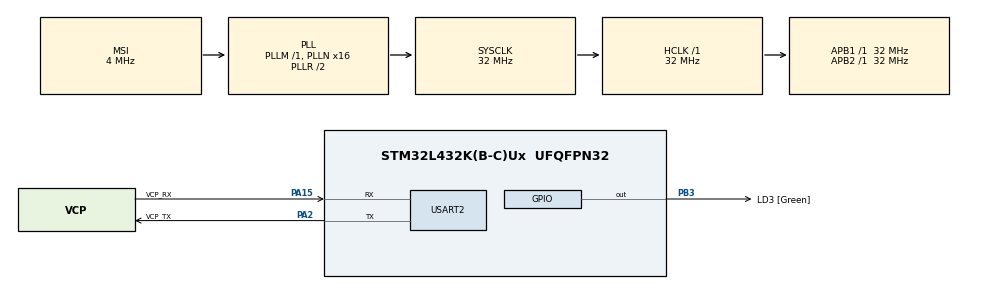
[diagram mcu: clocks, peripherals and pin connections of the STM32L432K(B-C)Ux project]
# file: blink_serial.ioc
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Mcu.Family=STM32L4
Mcu.Name=STM32L432K(B-C)Ux
Mcu.Package=UFQFPN32
NVIC.PriorityGroup=NVIC_PRIORITYGROUP_4
PA0.GPIO_Label=MCO [High speed clock in]
PA0.Mode=HSE-External-Clock-Source-for-LittleOrca
PA0.Signal=RCC_CK_IN
PA13\ (JTMS-SWDIO).GPIO_Label=SWDIO
PA13\ (JTMS-SWDIO).Mode=Serial_Wire
PA13\ (JTMS-SWDIO).Signal=SYS_JTMS-SWDIO
PA14\ (JTCK-SWCLK).GPIO_Label=SWCLK
PA14\ (JTCK-SWCLK).Mode=Serial_Wire
PA14\ (JTCK-SWCLK).Signal=SYS_JTCK-SWCLK
PA15\ (JTDI).GPIO_Label=VCP_RX
PA15\ (JTDI).Mode=Asynchronous
PA15\ (JTDI).Signal=USART2_RX
PA2.GPIO_Label=VCP_TX
PA2.Mode=Asynchronous
PA2.Signal=USART2_TX
PB3\ (JTDO-TRACESWO).GPIO_Label=LD3 [Green]
PB3\ (JTDO-TRACESWO).Signal=GPIO_Output
PC14-OSC32_IN\ (PC14).Mode=LSE-External-Oscillator
PC14-OSC32_IN\ (PC14).Signal=RCC_OSC32_IN
PC15-OSC32_OUT\ (PC15).Mode=LSE-External-Oscillator
PC15-OSC32_OUT\ (PC15).Signal=RCC_OSC32_OUT
ProjectManager.HeapSize=0x200
ProjectManager.StackSize=0x400
ProjectManager.TargetToolchain=STM32CubeIDE
RCC.AHBFreq_Value=32000000
RCC.APB1Freq_Value=32000000
RCC.APB1TimFreq_Value=32000000
RCC.APB2Freq_Value=32000000
RCC.APB2TimFreq_Value=32000000
RCC.CortexFreq_Value=32000000
RCC.HCLKFreq_Value=32000000
RCC.HSE_VALUE=8000000
RCC.HSI16_VALUE=16000000
RCC.HSI48_VALUE=48000000
RCC.HSI_VALUE=16000000
RCC.MSI_VALUE=4000000
RCC.PLLMUL=RCC_PLLMUL_4
RCC.PLLN=16
RCC.SYSCLKFreq_VALUE=32000000
RCC.SYSCLKSource=RCC_SYSCLKSOURCE_PLLCLK
RCC.VCOOutputFreq_Value=64000000
USART2.VirtualMode-Asynchronous=VM_ASYNC
board=NUCLEO-L432KC

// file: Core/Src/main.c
/* USER CODE BEGIN Header */
/**
  ******************************************************************************
  * @file           : main.c
  * @brief          : Main program body
  ******************************************************************************
  * @attention
  *
  * <h2><center>&copy; Copyright (c) 2020 STMicroelectronics.
  * All rights reserved.</center></h2>
  *
  * This software component is licensed by ST under BSD 3-Clause license,
  * the "License"; You may not use this file except in compliance with the
  * License. You may obtain a copy of the License at:
  *                        opensource.org/licenses/BSD-3-Clause
  *
  ******************************************************************************
  */
/* USER CODE END Header */

#include "main.h"

/* USER CODE BEGIN Includes */
#include "stdio.h"
#include "string.h"
/* USER CODE END Includes */

UART_HandleTypeDef huart2;

void SystemClock_Config(void);
static void MX_GPIO_Init(void);
static void MX_USART2_UART_Init(void);

int main(void)
{

  /* MCU Configuration--------------------------------------------------------*/

  /* Reset of all peripherals, Initializes the Flash interface and the Systick. */
  HAL_Init();

  /* Configure the system clock */
  SystemClock_Config();

  /* Initialize all configured peripherals */
  MX_GPIO_Init();
  MX_USART2_UART_Init();

  /* Infinite loop */
  /* USER CODE BEGIN WHILE */
  while (1)
  {
	  HAL_GPIO_WritePin(LD3_GPIO_Port, LD3_Pin, GPIO_PIN_SET);
	  printf("LED NYALA\r\n");
	  HAL_Delay(1000);
	  HAL_GPIO_WritePin(LD3_GPIO_Port, LD3_Pin, GPIO_PIN_RESET);
	  printf("LED PADAM\r\n");
	  HAL_Delay(1000);
    /* USER CODE END WHILE */

  }
}

void SystemClock_Config(void)
{
  RCC_OscInitTypeDef RCC_OscInitStruct = {0};
  RCC_ClkInitTypeDef RCC_ClkInitStruct = {0};
  RCC_PeriphCLKInitTypeDef PeriphClkInit = {0};

  /** Configure LSE Drive Capability
  */
  HAL_PWR_EnableBkUpAccess();
  __HAL_RCC_LSEDRIVE_CONFIG(RCC_LSEDRIVE_LOW);
  /** Initializes the CPU, AHB and APB busses clocks
  */
  RCC_OscInitStruct.OscillatorType = RCC_OSCILLATORTYPE_LSE|RCC_OSCILLATORTYPE_MSI;
  RCC_OscInitStruct.LSEState = RCC_LSE_ON;
  RCC_OscInitStruct.MSIState = RCC_MSI_ON;
  RCC_OscInitStruct.MSICalibrationValue = 0;
  RCC_OscInitStruct.MSIClockRange = RCC_MSIRANGE_6;
  RCC_OscInitStruct.PLL.PLLState = RCC_PLL_ON;
  RCC_OscInitStruct.PLL.PLLSource = RCC_PLLSOURCE_MSI;
  RCC_OscInitStruct.PLL.PLLM = 1;
  RCC_OscInitStruct.PLL.PLLN = 16;
  RCC_OscInitStruct.PLL.PLLP = RCC_PLLP_DIV7;
  RCC_OscInitStruct.PLL.PLLQ = RCC_PLLQ_DIV2;
  RCC_OscInitStruct.PLL.PLLR = RCC_PLLR_DIV2;
  if (HAL_RCC_OscConfig(&RCC_OscInitStruct) != HAL_OK)
  {
    Error_Handler();
  }
  /** Initializes the CPU, AHB and APB busses clocks
  */
  RCC_ClkInitStruct.ClockType = RCC_CLOCKTYPE_HCLK|RCC_CLOCKTYPE_SYSCLK
                              |RCC_CLOCKTYPE_PCLK1|RCC_CLOCKTYPE_PCLK2;
  RCC_ClkInitStruct.SYSCLKSource = RCC_SYSCLKSOURCE_PLLCLK;
  RCC_ClkInitStruct.AHBCLKDivider = RCC_SYSCLK_DIV1;
  RCC_ClkInitStruct.APB1CLKDivider = RCC_HCLK_DIV1;
  RCC_ClkInitStruct.APB2CLKDivider = RCC_HCLK_DIV1;

  if (HAL_RCC_ClockConfig(&RCC_ClkInitStruct, FLASH_LATENCY_1) != HAL_OK)
  {
    Error_Handler();
  }
  PeriphClkInit.PeriphClockSelection = RCC_PERIPHCLK_USART2;
  PeriphClkInit.Usart2ClockSelection = RCC_USART2CLKSOURCE_PCLK1;
  if (HAL_RCCEx_PeriphCLKConfig(&PeriphClkInit) != HAL_OK)
  {
    Error_Handler();
  }
  /** Configure the main internal regulator output voltage
  */
  if (HAL_PWREx_ControlVoltageScaling(PWR_REGULATOR_VOLTAGE_SCALE1) != HAL_OK)
  {
    Error_Handler();
  }
  /** Enable MSI Auto calibration
  */
  HAL_RCCEx_EnableMSIPLLMode();
}

static void MX_USART2_UART_Init(void)
{

  huart2.Instance = USART2;
  huart2.Init.BaudRate = 115200;
  huart2.Init.WordLength = UART_WORDLENGTH_8B;
  huart2.Init.StopBits = UART_STOPBITS_1;
  huart2.Init.Parity = UART_PARITY_NONE;
  huart2.Init.Mode = UART_MODE_TX_RX;
  huart2.Init.HwFlowCtl = UART_HWCONTROL_NONE;
  huart2.Init.OverSampling = UART_OVERSAMPLING_16;
  huart2.Init.OneBitSampling = UART_ONE_BIT_SAMPLE_DISABLE;
  huart2.AdvancedInit.AdvFeatureInit = UART_ADVFEATURE_NO_INIT;
  if (HAL_UART_Init(&huart2) != HAL_OK)
  {
    Error_Handler();
  }

}

static void MX_GPIO_Init(void)
{
  GPIO_InitTypeDef GPIO_InitStruct = {0};

  /* GPIO Ports Clock Enable */
  __HAL_RCC_GPIOC_CLK_ENABLE();
  __HAL_RCC_GPIOA_CLK_ENABLE();
  __HAL_RCC_GPIOB_CLK_ENABLE();

  /*Configure GPIO pin Output Level */
  HAL_GPIO_WritePin(LD3_GPIO_Port, LD3_Pin, GPIO_PIN_RESET);

  /*Configure GPIO pin : LD3_Pin */
  GPIO_InitStruct.Pin = LD3_Pin;
  GPIO_InitStruct.Mode = GPIO_MODE_OUTPUT_PP;
  GPIO_InitStruct.Pull = GPIO_NOPULL;
  GPIO_InitStruct.Speed = GPIO_SPEED_FREQ_LOW;
  HAL_GPIO_Init(LD3_GPIO_Port, &GPIO_InitStruct);

}

/* USER CODE BEGIN 4 */
int __io_putchar(int ch)
{
    HAL_UART_Transmit(&huart2, (uint8_t *)&ch, 1, 0xFFFF);
    return ch;
}

int __io_getchar(void)
{
    int ch = 0;
    while(!__HAL_UART_GET_FLAG(&huart2, UART_FLAG_RXNE));
    HAL_UART_Receive(&huart2, (uint8_t *)&ch, 1, 0xFFFF);
    return ch;
}

/* USER CODE END 4 */

void Error_Handler(void)
{
}

/************************ (C) COPYRIGHT STMicroelectronics *****END OF FILE****/
